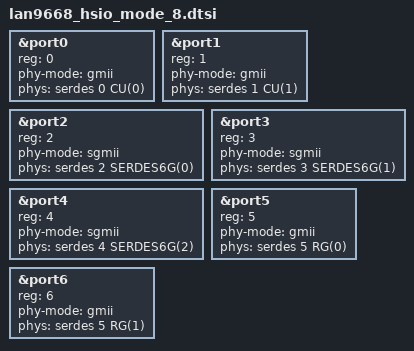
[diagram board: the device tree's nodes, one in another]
// SPDX-License-Identifier: (GPL-2.0+ OR MIT)

&port0 {
	reg = <0>;
	phy-mode = "gmii";
	phys = <&serdes 0 CU(0)>;
};

&port1 {
	reg = <1>;
	phy-mode = "gmii";
	phys = <&serdes 1 CU(1)>;
};

&port2 {
	reg = <2>;
	phy-mode = "sgmii";
	phys = <&serdes 2 SERDES6G(0)>;
};

&port3 {
	reg = <3>;
	phy-mode = "sgmii";
	phys = <&serdes 3 SERDES6G(1)>;
};

&port4 {
	reg = <4>;
	phy-mode = "sgmii";
	phys = <&serdes 4 SERDES6G(2)>;
};

&port5 {
	reg = <5>;
	phy-mode = "gmii";
	phys = <&serdes 5 RG(0)>;
};

&port6 {
	reg = <6>;
	phy-mode = "gmii";
	phys = <&serdes 5 RG(1)>;
};
